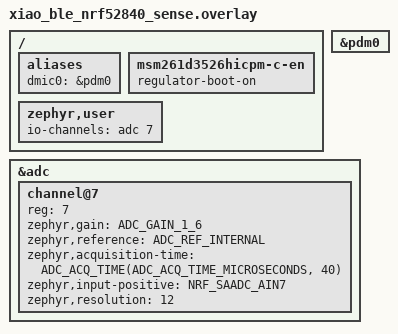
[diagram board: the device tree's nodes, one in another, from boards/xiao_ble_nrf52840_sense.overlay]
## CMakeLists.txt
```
cmake_minimum_required(VERSION 3.20.0)

# The SonicMesh library is a Zephyr module two levels up.
list(APPEND ZEPHYR_EXTRA_MODULES ${CMAKE_CURRENT_SOURCE_DIR}/../..)

find_package(Zephyr REQUIRED HINTS $ENV{ZEPHYR_BASE})
project(sonicmesh_node)

target_sources(app PRIVATE src/main.c)
```

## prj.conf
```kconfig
CONFIG_SM_ROLE_NODE=y
CONFIG_SM_DETECTOR_DRONE_COMB=y
CONFIG_SM_DETECTOR_GUNSHOT=y
CONFIG_SM_DETECTOR_DEPLOY_TONES=y
CONFIG_REGULATOR=y
CONFIG_BT_PER_ADV_SYNC=y
CONFIG_ADC=y
```

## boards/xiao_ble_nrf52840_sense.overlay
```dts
/* Power the on-board PDM mic at boot and name it for the dmic API. */
/ {
	aliases {
		dmic0 = &pdm0;
	};

	msm261d3526hicpm-c-en {
		regulator-boot-on;
	};
};

&pdm0 {
	status = "okay";
};

/* Battery: VBAT -> 1 M -> P0.31 (AIN7) -> 510 k -> P0.14. lib/battery.c holds P0.14 low. */
#include <zephyr/dt-bindings/adc/adc.h>
#include <zephyr/dt-bindings/adc/nrf-saadc.h>

/ {
	zephyr,user {
		io-channels = <&adc 7>;
	};
};

&adc {
	#address-cells = <1>;
	#size-cells = <0>;

	channel@7 {
		reg = <7>;
		zephyr,gain = "ADC_GAIN_1_6";
		zephyr,reference = "ADC_REF_INTERNAL";
		/* The divider is a high-impedance source (about 340 k): give the sample cap time. */
		zephyr,acquisition-time = <ADC_ACQ_TIME(ADC_ACQ_TIME_MICROSECONDS, 40)>;
		zephyr,input-positive = <NRF_SAADC_AIN7>;
		zephyr,resolution = <12>;
	};
};
```

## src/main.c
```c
/* SonicMesh sensor node: mic capture, every enabled detector, and the Coded PHY broadcast. */
#include <zephyr/kernel.h>

#include <sonicmesh/audio.h>
#include <sonicmesh/diag.h>
#include <sonicmesh/param.h>
#include <sonicmesh/msg.h>
#include <sonicmesh/radio.h>
#include <sonicmesh/status_led.h>

int main(void)
{
	sm_led_init();
	sm_led_flash(SM_LED_GREEN, 500);
	k_msleep(1500); /* give a serial monitor time to attach */
	printk("SonicMesh node %04x\n", sm_node_id());
	sm_diag_print();
	sm_params_init(); /* before anything reads a parameter */

	if (sm_radio_start() != 0) {
		sm_led_set(SM_LED_RED, true);
		return 0;
	}
	if (sm_audio_start() != 0) {
		sm_led_set(SM_LED_RED, true);
		return 0;
	}
	sm_health_start();
	return 0;
}
```
